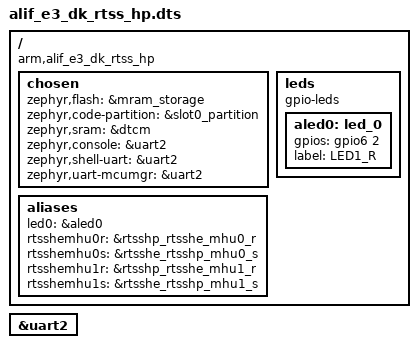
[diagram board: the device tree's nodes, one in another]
/* Copyright (c) 2024 Alif Semiconductor
 *
 * SPDX-License-Identifier: Apache-2.0
 */
/dts-v1/;

#include <alif/e3_rtss_common.dtsi>
#include <alif/ensemble_rtss_hp.dtsi>
#include <alif/ensemble-pinctrl.dtsi>

/ {
	compatible = "arm,alif_e3_dk_rtss_hp";
	#address-cells = <1>;
	#size-cells = <1>;

	chosen {
		zephyr,flash = &mram_storage;
		zephyr,code-partition = &slot0_partition;
		zephyr,sram = &dtcm;
		zephyr,console = &uart2;
		zephyr,shell-uart = &uart2;
		zephyr,uart-mcumgr = &uart2;
	};

	aliases {
		led0 = &aled0;
		rtsshemhu0r = &rtsshp_rtsshe_mhu0_r;
		rtsshemhu0s = &rtsshe_rtsshp_mhu0_s;
		rtsshemhu1r = &rtsshp_rtsshe_mhu1_r;
		rtsshemhu1s = &rtsshe_rtsshp_mhu1_s;
	};
	leds {
		compatible = "gpio-leds";
		aled0: led_0 {
			gpios = <&gpio6 2 0>;
			label = "LED1_R";
		};
	};
};
&uart2 {
	status = "okay";
};
